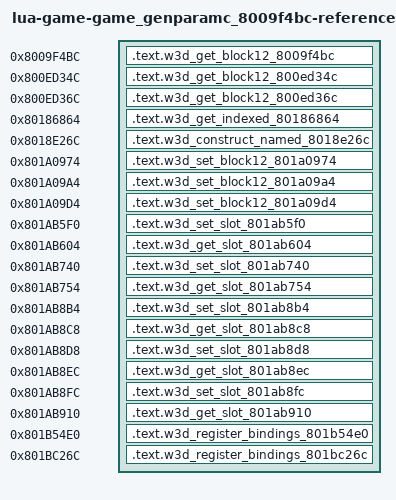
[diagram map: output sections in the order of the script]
/* Generated reference-only placements. All bodies are source-built. */
OUTPUT_FORMAT("elf32-powerpc")
OUTPUT_ARCH(powerpc)
ENTRY(w3d_get_block12_8009f4bc)
_SDA_BASE_ = 0x804b2540;
_SDA2_BASE_ = 0x804c2540;
fn_801e8d9c = 0x801e8d9c;
fn_801ea0ec = 0x801ea0ec;
fn_801ebf38 = 0x801ebf38;
fn_801ecc6c = 0x801ecc6c;
fn_8020c5c0 = 0x8020c5c0;
fn_80341884 = 0x80341884;
lbl_803aad38 = 0x803aad38;
lbl_803aad68 = 0x803aad68;
lbl_803aad98 = 0x803aad98;
lbl_803aadc4 = 0x803aadc4;
lbl_803ab73c = 0x803ab73c;
lbl_803ab770 = 0x803ab770;
lbl_803ab7a4 = 0x803ab7a4;
lbl_803ab7d8 = 0x803ab7d8;
lbl_804131d8 = 0x804131d8;
lbl_804b06a0 = 0x804b06a0;
SECTIONS {
  .text.w3d_get_block12_8009f4bc 0x8009f4bc : { *(.text.w3d_get_block12_8009f4bc) }
  .text.w3d_get_block12_800ed34c 0x800ed34c : { *(.text.w3d_get_block12_800ed34c) }
  .text.w3d_get_block12_800ed36c 0x800ed36c : { *(.text.w3d_get_block12_800ed36c) }
  .text.w3d_get_indexed_80186864 0x80186864 : { *(.text.w3d_get_indexed_80186864) }
  .text.w3d_construct_named_8018e26c 0x8018e26c : { *(.text.w3d_construct_named_8018e26c) }
  .text.w3d_set_block12_801a0974 0x801a0974 : { *(.text.w3d_set_block12_801a0974) }
  .text.w3d_set_block12_801a09a4 0x801a09a4 : { *(.text.w3d_set_block12_801a09a4) }
  .text.w3d_set_block12_801a09d4 0x801a09d4 : { *(.text.w3d_set_block12_801a09d4) }
  .text.w3d_set_slot_801ab5f0 0x801ab5f0 : { *(.text.w3d_set_slot_801ab5f0) }
  .text.w3d_get_slot_801ab604 0x801ab604 : { *(.text.w3d_get_slot_801ab604) }
  .text.w3d_set_slot_801ab740 0x801ab740 : { *(.text.w3d_set_slot_801ab740) }
  .text.w3d_get_slot_801ab754 0x801ab754 : { *(.text.w3d_get_slot_801ab754) }
  .text.w3d_set_slot_801ab8b4 0x801ab8b4 : { *(.text.w3d_set_slot_801ab8b4) }
  .text.w3d_get_slot_801ab8c8 0x801ab8c8 : { *(.text.w3d_get_slot_801ab8c8) }
  .text.w3d_set_slot_801ab8d8 0x801ab8d8 : { *(.text.w3d_set_slot_801ab8d8) }
  .text.w3d_get_slot_801ab8ec 0x801ab8ec : { *(.text.w3d_get_slot_801ab8ec) }
  .text.w3d_set_slot_801ab8fc 0x801ab8fc : { *(.text.w3d_set_slot_801ab8fc) }
  .text.w3d_get_slot_801ab910 0x801ab910 : { *(.text.w3d_get_slot_801ab910) }
  .text.w3d_register_bindings_801b54e0 0x801b54e0 : { *(.text.w3d_register_bindings_801b54e0) }
  .text.w3d_register_bindings_801bc26c 0x801bc26c : { *(.text.w3d_register_bindings_801bc26c) }
  /DISCARD/ : { *(.text*) *(.rodata*) *(.data*) *(.bss*) *(.sdata*) *(.sbss*) *(.comment) }
}
